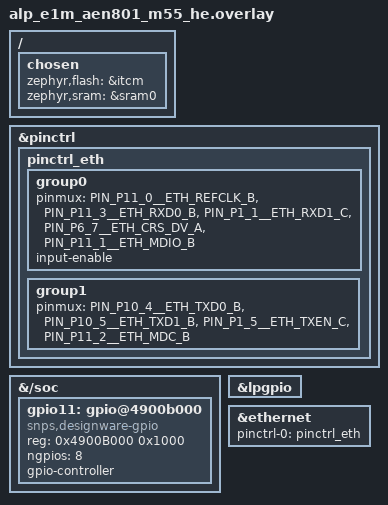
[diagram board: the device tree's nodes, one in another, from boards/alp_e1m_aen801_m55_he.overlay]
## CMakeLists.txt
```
# SPDX-License-Identifier: Apache-2.0
cmake_minimum_required(VERSION 3.20)
find_package(Zephyr REQUIRED HINTS $ENV{ZEPHYR_BASE})
project(aen_ethernet_link LANGUAGES C)
target_sources(app PRIVATE src/main.c)
```

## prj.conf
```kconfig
# SPDX-License-Identifier: Apache-2.0
#
# Bench config for the E1M-AEN801 (M55-HE). Console is the E1M edge UART0.

CONFIG_ALP_SDK=y

# Networking + Ethernet L2 + the alp-sdk Alif GMAC glue (CONFIG_ETH_DWMAC_ALIF
# selects the upstream eth_dwmac core). IPv4 on; no auto DHCP (no link on this
# bench until the PHY is powered, so a DHCP client would just spin).
CONFIG_NETWORKING=y
CONFIG_NET_L2_ETHERNET=y
CONFIG_ETH_DWMAC_ALIF=y
CONFIG_NET_IPV4=y
CONFIG_NET_IPV6=n
CONFIG_NET_UDP=y
CONFIG_NET_CONFIG_AUTO_INIT=n

# DEFINITIVE link proof: pull a DHCP lease off the bench switch (dnsmasq,
# its DHCP pool). A lease requires a genuine bidirectional link.
CONFIG_NET_DHCPV4=y
CONFIG_NET_MGMT=y
CONFIG_NET_MGMT_EVENT=y
# DHCP needs sys_rand_get (transaction IDs); no HW RNG wired -> timer PRNG
# (TEST_RANDOM_GENERATOR enables the non-crypto choice; bench link test only).
CONFIG_TEST_RANDOM_GENERATOR=y
CONFIG_NET_PKT_RX_COUNT=8
CONFIG_NET_PKT_TX_COUNT=8
CONFIG_NET_BUF_RX_COUNT=16
CONFIG_NET_BUF_TX_COUNT=16

# Per-interface RX byte stats (a secondary proof; fixed-link masks carrier).
CONFIG_NET_STATISTICS=y
CONFIG_NET_STATISTICS_PER_INTERFACE=y

# GPIO for the PHY power-down (P15_4 lpgpio) + reset (P11_6 gpio11) lines.
CONFIG_GPIO=y

CONFIG_MAIN_STACK_SIZE=4096
CONFIG_HEAP_MEM_POOL_SIZE=16384

# eth_dwmac uses DMA descriptor rings -- keep the data path coherent on the M55.
CONFIG_DCACHE=n

# Console: Alp UART console -- E1M edge UART0 (Alif UART5, P3_4/P3_5, 115200
# 8N1, NS16550), the E1M-AEN801 carrier console. The board _defconfig already
# selects it; we set it explicitly here so the example is self-describing.
CONFIG_SERIAL=y
CONFIG_CONSOLE=y
CONFIG_UART_CONSOLE=y
CONFIG_UART_INTERRUPT_DRIVEN=y
# Serial-less bench? Comment the four lines above and uncomment these to read
# 'ram_console_buf' over SWD instead:
# CONFIG_RAM_CONSOLE=y
# CONFIG_RAM_CONSOLE_BUFFER_SIZE=2048
# CONFIG_UART_CONSOLE=n
CONFIG_PRINTK=y
```

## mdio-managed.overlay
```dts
/*
 * Copyright 2026 Alp Lab AB
 * SPDX-License-Identifier: Apache-2.0
 *
 * MDIO-managed-PHY compile-only variant of the aen-ethernet-link bring-up.
 * Applied ON TOP of the board's default fixed-link overlay
 * (boards/alp_e1m_aen801_m55_he_ae822fa0e5597ls0_rtss_he.overlay, which
 * already routes the MDC/MDIO pins in pinctrl_eth): enables the `mdio`
 * controller + `eth_phy_managed` TI DP83825 child added to
 * zephyr/dts/alif/ensemble_e8_peripherals.dtsi, and repoints &ethernet's
 * phy-handle at it instead of the default fixed-link eth_phy.
 *
 * COMPILE-PROOF in CI (see the mdio-managed test entry in testcase.yaml):
 * closes that the mdio_dwmac_alif driver binds, phy_ti_dp83825 binds on the
 * bus, and the upstream eth_dwmac core's phy_link path compiles with a
 * managed PHY.
 *
 * The MDIO layer itself HAS since been exercised on real E8 silicon by a
 * Flow C ITCM RAM-run of this variant (#1244):
 *
 *   [eth] MDIO PHY@0 id=2000a140 (DP83825=2000a140)
 *   [eth] PHY regs: ANAR=01e1 ANLPAR=0000 PHYSTS=0002 RCSR=00e1
 *
 * That run reported `PHY link DOWN (BMSR=7849)` -- no cable on that desk --
 * so link/traffic over the managed path is still unproven; reading the PHY
 * ID needs no link, which is what made the address answerable without one.
 *
 * This overlay deliberately does NOT override `reg`: it inherits the PHY
 * address from `eth_phy_managed` in
 * zephyr/dts/alif/ensemble_e8_peripherals.dtsi, so there is ONE source of
 * truth for it. Keep it that way -- the fix for the wrong address (1 -> 0)
 * belongs at that node, not here.
 */

&mdio {
	status = "okay";
};

&eth_phy_managed {
	status = "okay";
};

&ethernet {
	phy-handle = <&eth_phy_managed>;
};
```

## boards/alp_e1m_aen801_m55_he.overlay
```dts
/*
 * Copyright (c) 2026 Alp Lab AB
 * SPDX-License-Identifier: Apache-2.0
 *
 * Ethernet (GMAC) bring-up overlay for the E1M-AEN801 (E8, M55-HE).
 *
 * The ethernet@48100000 node (eth_dwmac core + the alp-sdk alif,ethernet glue,
 * fixed-link RMII PHY) already lives in zephyr/dts/alif/ensemble_e8_peripherals.dtsi
 * as status="disabled"; this overlay enables it and supplies the RMII pin group +
 * a real MAC address.
 *
 * RMII PADS: the AUTHORITATIVE E1M-AEN801 routing from
 * metadata/e1m_modules/aen/alif-ethernet-phy.tsv (NOT the fork's reference route,
 * which the first cut wrongly used):
 *   REFCLK P11_0 | RXD0 P11_3 | RXD1 P1_1 | CRS_DV P6_7  (inputs)
 *   TXD0  P10_4  | TXD1 P10_5 | TXEN  P1_5               (outputs)
 * The input pads carry `input-enable` (the upstream pad REN bit, set by
 * soc/alif/ensemble/pinctrl_soc.h) so the RMII RX buffers actually sense. The PHY
 * is unmanaged (fixed-link) so MDC/MDIO (P11_2/P11_1) are not muxed.
 *
 * PHY POWER/RESET are ALIF pins (per the SoM TSV), NOT CC3501E as the first cut
 * claimed: E_PHY_PWRDWN = P15_4 (lpgpio) and E_PHY_RESET = P11_6 (gpio11). Both
 * are driven by main(); the alp-sdk E8 dtsi already carries gpio0..gpio9 AND
 * lpgpio, so lpgpio just needs status="okay" -- only gpio11 is newly created
 * here (reg/IRQ/ngpios from the fork dtsi).
 */
#include <zephyr/dt-bindings/pinctrl/alif-ensemble-pinctrl.h>

/ {
	chosen {
		zephyr,flash = &itcm; /* bench RAM/SES-load; path-ref form */
		/delete-property/ zephyr,code-partition;
		/*
		 * Put SYSTEM RAM in the global on-chip SRAM0 (sram@2000000, 4 MiB,
		 * @0x02000000 -- declared by the SoC dtsi, the same bank the NPU uses),
		 * NOT the generated default `zephyr,sram = &dtcm`. The GMAC is a DMA bus
		 * master: it fetches the descriptor rings and reads/writes the net_buf
		 * packet pool over its own AXI master. The M55 DTCM (CPU-local alias
		 * 0x20000000) is tightly-coupled and NOT on the GMAC DMA path, so rings +
		 * buffers left in DTCM are invisible to the DMA -- no frames move in
		 * EITHER direction (bench: SOM rx_bytes=0 AND the switch/server NIC RX=0).
		 * SRAM0 is globally addressed (CPU addr == DMA addr), which is exactly
		 * what the upstream DWMAC core needs (it hands the raw CPU pointer to the
		 * DMA -- no local_to_global translation). With CONFIG_DCACHE=n (prj.conf)
		 * the CPU and the DMA share a coherent view. This is the eth_dwmac glue's
		 * documented Tier-1.5 placement gap (see eth_dwmac_alif_ensemble.c header).
		 */
		zephyr,sram = &sram0;
	};
};

&pinctrl {
	pinctrl_eth: pinctrl_eth {
		/* RMII inputs (REFCLK + RX) + MDIO (bidirectional, read during MDIO
		 * transactions) -- input-enable sets the pad REN bit so they sense.
		 * MDC/MDIO = P11_2/P11_1 (SoM TSV) let us read the PHY status registers. */
		group0 {
			pinmux = <PIN_P11_0__ETH_REFCLK_B>, <PIN_P11_3__ETH_RXD0_B>,
				 <PIN_P1_1__ETH_RXD1_C>, <PIN_P6_7__ETH_CRS_DV_A>,
				 <PIN_P11_1__ETH_MDIO_B>;
			input-enable;
		};
		/* RMII outputs (TX) + MDC (MDIO clock). */
		group1 {
			pinmux = <PIN_P10_4__ETH_TXD0_B>, <PIN_P10_5__ETH_TXD1_B>,
				 <PIN_P1_5__ETH_TXEN_C>, <PIN_P11_2__ETH_MDC_B>;
		};
	};
};

/* PHY reset line E_PHY_RESET = P11_6 (gpio11 pin 6). gpio11@4900b000 from the
 * fork dts (snps,designware-gpio, ngpios 8, IRQ 267..). */
&{/soc} {
	gpio11: gpio@4900b000 {
		compatible = "snps,designware-gpio";
		reg = <0x4900B000 0x1000>;
		ngpios = <8>;
		gpio-controller;
		#gpio-cells = <2>;
		status = "okay";
	};
};

/* PHY power-down line E_PHY_PWRDWN = P15_4 (lpgpio pin 4). lpgpio@42002000
 * (AON/LP domain) already exists in the alp-sdk E8 dtsi; just enable it. */
&lpgpio {
	status = "okay";
};

&ethernet {
	pinctrl-0 = <&pinctrl_eth>;
	pinctrl-names = "default";
	/* Station MAC: inherits zephyr,random-mac-address from the SoC dtsi
	 * (per-boot random locally-administered 02:01:56:xx:xx:xx) -- DHCP
	 * doesn't care which MAC asks, and a random one means two boards on
	 * the same bench switch never collide.  To pin a fixed per-unit MAC
	 * instead:
	 *   /delete-property/ zephyr,random-mac-address;
	 *   local-mac-address = [ .. ]; */
	status = "okay";
};
```

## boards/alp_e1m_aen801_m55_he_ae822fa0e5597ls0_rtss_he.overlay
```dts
/*
 * Copyright (c) 2026 Alp Lab AB
 * SPDX-License-Identifier: Apache-2.0
 *
 * Ethernet (GMAC) bring-up overlay for the E1M-AEN801 (E8, M55-HE).
 *
 * The ethernet@48100000 node (eth_dwmac core + the alp-sdk alif,ethernet glue,
 * fixed-link RMII PHY) already lives in zephyr/dts/alif/ensemble_e8_peripherals.dtsi
 * as status="disabled"; this overlay enables it and supplies the RMII pin group +
 * a real MAC address.
 *
 * RMII PADS: the AUTHORITATIVE E1M-AEN801 routing from
 * metadata/e1m_modules/aen/alif-ethernet-phy.tsv (NOT the fork's reference route,
 * which the first cut wrongly used):
 *   REFCLK P11_0 | RXD0 P11_3 | RXD1 P1_1 | CRS_DV P6_7  (inputs)
 *   TXD0  P10_4  | TXD1 P10_5 | TXEN  P1_5               (outputs)
 * The input pads carry `input-enable` (the upstream pad REN bit, set by
 * soc/alif/ensemble/pinctrl_soc.h) so the RMII RX buffers actually sense. The PHY
 * is unmanaged (fixed-link) so MDC/MDIO (P11_2/P11_1) are not muxed.
 *
 * PHY POWER/RESET are ALIF pins (per the SoM TSV), NOT CC3501E as the first cut
 * claimed: E_PHY_PWRDWN = P15_4 (lpgpio) and E_PHY_RESET = P11_6 (gpio11). Both
 * are driven by main(); the alp-sdk E8 dtsi already carries gpio0..gpio9 AND
 * lpgpio, so lpgpio just needs status="okay" -- only gpio11 is newly created
 * here (reg/IRQ/ngpios from the fork dtsi).
 */
#include <zephyr/dt-bindings/pinctrl/alif-ensemble-pinctrl.h>

/ {
	chosen {
		zephyr,flash = &itcm; /* bench RAM/SES-load; path-ref form */
		/delete-property/ zephyr,code-partition;
		/*
		 * Main RAM stays on the generated default `zephyr,sram = &dtcm` --
		 * unlike the first cut, this overlay does NOT move all of RAM to
		 * SRAM0 (slower, and intermittently broke the ISP). The GMAC DMA
		 * still cannot reach DTCM, so only the Ethernet-owned buffers move:
		 * the ethernet node's `memory-region = <&sram0>;` (SoC dtsi) places
		 * the descriptor rings there, and CONFIG_ETH_DWMAC_ALIF_NET_BUF_IN_DMA_REGION
		 * (prj.conf) relocates the net_buf packet pool (subsys/net/ip/net_pkt.c)
		 * into the same region. See eth_dwmac_alif_ensemble.c's file header
		 * for the full placement rationale; CONFIG_DCACHE=n (prj.conf) keeps
		 * the CPU and the DMA coherent.
		 */
	};
};

&pinctrl {
	pinctrl_eth: pinctrl_eth {
		/* RMII inputs (REFCLK + RX) + MDIO (bidirectional, read during MDIO
		 * transactions) -- input-enable sets the pad REN bit so they sense.
		 * MDC/MDIO = P11_2/P11_1 (SoM TSV) let us read the PHY status registers. */
		group0 {
			pinmux = <PIN_P11_0__ETH_REFCLK_B>, <PIN_P11_3__ETH_RXD0_B>,
				 <PIN_P1_1__ETH_RXD1_C>, <PIN_P6_7__ETH_CRS_DV_A>,
				 <PIN_P11_1__ETH_MDIO_B>;
			input-enable;
		};
		/* RMII outputs (TX) + MDC (MDIO clock). */
		group1 {
			pinmux = <PIN_P10_4__ETH_TXD0_B>, <PIN_P10_5__ETH_TXD1_B>,
				 <PIN_P1_5__ETH_TXEN_C>, <PIN_P11_2__ETH_MDC_B>;
		};
	};
};

/* PHY reset line E_PHY_RESET = P11_6 (gpio11 pin 6). gpio11@4900b000 from the
 * fork dts (snps,designware-gpio, ngpios 8, IRQ 267..). */
&{/soc} {
	gpio11: gpio@4900b000 {
		compatible = "snps,designware-gpio";
		reg = <0x4900B000 0x1000>;
		ngpios = <8>;
		gpio-controller;
		#gpio-cells = <2>;
		status = "okay";
	};
};

/* PHY power-down line E_PHY_PWRDWN = P15_4 (lpgpio pin 4). lpgpio@42002000
 * (AON/LP domain) already exists in the alp-sdk E8 dtsi; just enable it. */
&lpgpio {
	status = "okay";
};

&ethernet {
	pinctrl-0 = <&pinctrl_eth>;
	pinctrl-names = "default";
	/* Station MAC: inherits zephyr,random-mac-address from the SoC dtsi
	 * (per-boot random locally-administered 02:01:56:xx:xx:xx) -- DHCP
	 * doesn't care which MAC asks, and a random one means two boards on
	 * the same bench switch never collide.  To pin a fixed per-unit MAC
	 * instead:
	 *   /delete-property/ zephyr,random-mac-address;
	 *   local-mac-address = [ .. ]; */
	status = "okay";
};
```

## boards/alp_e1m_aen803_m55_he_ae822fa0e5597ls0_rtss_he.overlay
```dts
/*
 * Copyright (c) 2026 Alp Lab AB
 * SPDX-License-Identifier: Apache-2.0
 *
 * Ethernet (GMAC) bring-up overlay for the E1M-AEN803 (E8, M55-HE).
 *
 * The ethernet@48100000 node (eth_dwmac core + the alp-sdk alif,ethernet glue,
 * fixed-link RMII PHY) already lives in zephyr/dts/alif/ensemble_e8_peripherals.dtsi
 * as status="disabled"; this overlay enables it and supplies the RMII pin group +
 * a real MAC address.
 *
 * RMII PADS: the AUTHORITATIVE E1M-AEN803 routing from
 * metadata/e1m_modules/aen/alif-ethernet-phy.tsv (NOT the fork's reference route,
 * which the first cut wrongly used):
 *   REFCLK P11_0 | RXD0 P11_3 | RXD1 P1_1 | CRS_DV P6_7  (inputs)
 *   TXD0  P10_4  | TXD1 P10_5 | TXEN  P1_5               (outputs)
 * The input pads carry `input-enable` (the upstream pad REN bit, set by
 * soc/alif/ensemble/pinctrl_soc.h) so the RMII RX buffers actually sense. The PHY
 * is unmanaged (fixed-link) so MDC/MDIO (P11_2/P11_1) are not muxed.
 *
 * PHY POWER/RESET are ALIF pins (per the SoM TSV), NOT CC3501E as the first cut
 * claimed: E_PHY_PWRDWN = P15_4 (lpgpio) and E_PHY_RESET = P11_6 (gpio11). Both
 * are driven by main(); the alp-sdk E8 dtsi already carries gpio0..gpio9 AND
 * lpgpio, so lpgpio just needs status="okay" -- only gpio11 is newly created
 * here (reg/IRQ/ngpios from the fork dtsi).
 */
#include <zephyr/dt-bindings/pinctrl/alif-ensemble-pinctrl.h>

/ {
	chosen {
		zephyr,flash = &itcm; /* bench RAM/SES-load; path-ref form */
		/delete-property/ zephyr,code-partition;
		/*
		 * Main RAM stays on the generated default `zephyr,sram = &dtcm` --
		 * unlike the first cut, this overlay does NOT move all of RAM to
		 * SRAM0 (slower, and intermittently broke the ISP). The GMAC DMA
		 * still cannot reach DTCM, so only the Ethernet-owned buffers move:
		 * the ethernet node's `memory-region = <&sram0>;` (SoC dtsi) places
		 * the descriptor rings there, and CONFIG_ETH_DWMAC_ALIF_NET_BUF_IN_DMA_REGION
		 * (prj.conf) relocates the net_buf packet pool (subsys/net/ip/net_pkt.c)
		 * into the same region. See eth_dwmac_alif_ensemble.c's file header
		 * for the full placement rationale; CONFIG_DCACHE=n (prj.conf) keeps
		 * the CPU and the DMA coherent.
		 */
	};
};

&pinctrl {
	pinctrl_eth: pinctrl_eth {
		/* RMII inputs (REFCLK + RX) + MDIO (bidirectional, read during MDIO
		 * transactions) -- input-enable sets the pad REN bit so they sense.
		 * MDC/MDIO = P11_2/P11_1 (SoM TSV) let us read the PHY status registers. */
		group0 {
			pinmux = <PIN_P11_0__ETH_REFCLK_B>, <PIN_P11_3__ETH_RXD0_B>,
				 <PIN_P1_1__ETH_RXD1_C>, <PIN_P6_7__ETH_CRS_DV_A>,
				 <PIN_P11_1__ETH_MDIO_B>;
			input-enable;
		};
		/* RMII outputs (TX) + MDC (MDIO clock). */
		group1 {
			pinmux = <PIN_P10_4__ETH_TXD0_B>, <PIN_P10_5__ETH_TXD1_B>,
				 <PIN_P1_5__ETH_TXEN_C>, <PIN_P11_2__ETH_MDC_B>;
		};
	};
};

/* PHY reset line E_PHY_RESET = P11_6 (gpio11 pin 6). gpio11@4900b000 from the
 * fork dts (snps,designware-gpio, ngpios 8, IRQ 267..). */
&{/soc} {
	gpio11: gpio@4900b000 {
		compatible = "snps,designware-gpio";
		reg = <0x4900B000 0x1000>;
		ngpios = <8>;
		gpio-controller;
		#gpio-cells = <2>;
		status = "okay";
	};
};

/* PHY power-down line E_PHY_PWRDWN = P15_4 (lpgpio pin 4). lpgpio@42002000
 * (AON/LP domain) already exists in the alp-sdk E8 dtsi; just enable it. */
&lpgpio {
	status = "okay";
};

&ethernet {
	pinctrl-0 = <&pinctrl_eth>;
	pinctrl-names = "default";
	/* Station MAC: inherits zephyr,random-mac-address from the SoC dtsi
	 * (per-boot random locally-administered 02:01:56:xx:xx:xx) -- DHCP
	 * doesn't care which MAC asks, and a random one means two boards on
	 * the same bench switch never collide.  To pin a fixed per-unit MAC
	 * instead:
	 *   /delete-property/ zephyr,random-mac-address;
	 *   local-mac-address = [ .. ]; */
	status = "okay";
};
```

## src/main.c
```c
/*
 * Copyright (c) 2026 Alp Lab AB
 * SPDX-License-Identifier: Apache-2.0
 *
 * aen-ethernet-link -- bring up the Ensemble E8 GMAC (eth_dwmac core + the
 * alp-sdk "alif,ethernet" glue) on the E1M-AEN801 (M55-HE), power the on-module
 * TI DP83825 PHY (exact order code TBD -- metadata/chips/dp83825.yaml), and
 * test the link by pulling a DHCP lease off the bench switch.
 *
 * The MAC/driver/DT live in the SoC dtsi (ethernet@48100000, fixed-link RMII PHY);
 * the board overlay enables the node with the AUTHORITATIVE SoM RMII pin route
 * (alif-ethernet-phy.tsv) + input-enable on the RX pads, and adds the PHY control
 * GPIOs. This app:
 *   1. powers the PHY EARLY (SYS_INIT, before the eth driver's RMII ref-clock
 *      probe) -- E_PHY_PWRDWN=P15_4 (lpgpio.4) + E_PHY_RESET=P11_6 (gpio11.6).
 *      These are ALIF pins (per the SoM TSV), NOT CC3501E as first assumed.
 *   2. reads back which ref-clock source the driver's AUTO probe locked.
 *   3. requests a DHCP lease as the definitive end-to-end link test.
 *
 * RESULT PASS (bench-validated, both sides): the SOM pulls a real DHCP lease off
 * the bench switch (an address from the DHCP pool) and is REACHABLE in the server's ARP
 * table. Three things had to be right, in order:
 *   1. PHY power before the probe -> the AUTO probe selects the EXTERNAL 50 MHz
 *      oscillator (ETH_CTRL bit4: 1->0); the PHY is clocked. The "needs power
 *      enable" the bench called out IS this P15_4 enable.
 *   2. PHY RMII clock mode: RCSR bit7 REF_CLK_SEL=1 (50 MHz ref) -> media link up
 *      (BMSR bit2, 0x786d). bit7=0 keeps it down (0x7849).
 *   3. THE DECISIVE FIX -- DMA buffers off the DTCM. The board defaults
 *      `zephyr,sram = &dtcm`, so the GMAC descriptor rings + net_buf pool sat in
 *      the M55 DTCM, which is NOT on the GMAC DMA's bus -> zero frames moved
 *      either way (SOM rx_bytes=0 AND server NIC RX=0) even with the link up.
 *      Main RAM stays on DTCM (`zephyr,sram = &dtcm`, unchanged by this
 *      overlay) -- only the Ethernet-owned buffers move, via the SoC dtsi's
 *      ethernet node `memory-region = <&sram0>;` (descriptor rings) and
 *      CONFIG_ETH_DWMAC_ALIF_NET_BUF_IN_DMA_REGION (net_buf pool,
 *      subsys/net/ip/net_pkt.c), @0x02000000, CPU addr == DMA addr,
 *      + CONFIG_DCACHE=n. Silicon-verified on E1M-AEN803 (bench run 202:
 *      DHCP lease + ping, rings/pools in SRAM0, main RAM on DTCM);
 *      E1M-AEN801 is build-verified only. See the overlay and the
 *      eth_dwmac_alif_ensemble.c header (its documented Tier-1.5 gap).
 *
 * PASS gate: a DHCP lease is acquired (full bidirectional link). carrier_ok is
 * fixed-link synthetic (no managed PHY) and is NOT a link proof; the lease is.
 * PHY GPIO polarity is the conventional DP83825 reading (PWRDWN enable HIGH;
 * RST_N active-low).
 */

#include <stdio.h>
#include <errno.h>
#include <inttypes.h>

#include <zephyr/kernel.h>
#include <zephyr/init.h>
#include <zephyr/device.h>
#include <zephyr/drivers/gpio.h>
#include <zephyr/drivers/pinctrl.h>
#include <zephyr/dt-bindings/pinctrl/alif-ensemble-pinctrl.h>
#include <zephyr/sys/sys_io.h>
#include <zephyr/sys/util.h>
#include <zephyr/net/net_if.h>
#include <zephyr/net/ethernet.h>
#include <zephyr/net/dhcpv4.h>
#include <zephyr/net/net_ip.h>

#define PHY_RESET_PIN  6 /* E_PHY_RESET  = P11_6 (gpio11) */
#define PHY_PWRDWN_PIN 4 /* E_PHY_PWRDWN = P15_4 (lpgpio) */
#define LINK_SETTLE_MS 3000

/* Pad-mux states: gpio_dw applies no mux, so select the GPIO/LPGPIO function on
 * the two PHY-control pads through the Alif pinctrl driver (function 0). */
static const pinctrl_soc_pin_t phy_reset_mux[]  = { PIN_P11_6__GPIO };
static const pinctrl_soc_pin_t phy_pwrdwn_mux[] = { PIN_P15_4__LPGPIO };

/*
 * Power + reset the PHY EARLY -- at POST_KERNEL priority 50, AFTER the GPIO
 * controllers (40) but BEFORE the eth_dwmac driver (ETH_INIT_PRIORITY=60). The
 * glue's RMII ref-clock AUTO probe runs inside eth init and falls back to the
 * internal PLL if it sees no external 50 MHz clock at that moment; powering the
 * PHY/oscillator here (before that probe) lets the probe find the external clock
 * if the board just needed the enable. (When this ran later, in main(), the probe
 * had already fallen back -- SWD showed ETH_CTRL bit4=1 = internal PLL.)
 */
static int phy_power_init(void)
{
	const struct device *gpio11 = DEVICE_DT_GET(DT_NODELABEL(gpio11));
	const struct device *lpgpio = DEVICE_DT_GET(DT_NODELABEL(lpgpio));

	if (!device_is_ready(gpio11) || !device_is_ready(lpgpio)) {
		return -ENODEV;
	}

	pinctrl_configure_pins(phy_reset_mux, ARRAY_SIZE(phy_reset_mux), 0U);
	pinctrl_configure_pins(phy_pwrdwn_mux, ARRAY_SIZE(phy_pwrdwn_mux), 0U);

	/* Power-enable the PHY/oscillator. The user calls this a "power enable", so
	 * E_PHY_PWRDWN gates a board power switch (active-HIGH enable) -> drive HIGH.
	 * (SWD-verified the lpgpio follows; the SoM TSV gives the pad, not the
	 * polarity -- flip to low if this powers it down.) */
	gpio_pin_configure(lpgpio, PHY_PWRDWN_PIN, GPIO_OUTPUT_ACTIVE);
	gpio_pin_set(lpgpio, PHY_PWRDWN_PIN, 1);
	k_busy_wait(50000); /* let the PHY supply + its reference clock stabilize */

	/* Reset pulse, conventional DP83825 RST_N (active-low): LOW asserts, HIGH
	 * releases. Long assert + post-reset settle so the reference clock is stable
	 * across the reset (a clock that isn't stable at deassert leaves the analog
	 * front-end uninitialised). Both reset polarities were bench-tried. */
	gpio_pin_configure(gpio11, PHY_RESET_PIN, GPIO_OUTPUT_ACTIVE);
	gpio_pin_set(gpio11, PHY_RESET_PIN, 0); /* assert */
	k_busy_wait(50000);
	gpio_pin_set(gpio11, PHY_RESET_PIN, 1); /* release */
	k_busy_wait(100000);                    /* DP83825 post-reset settle (>=50 ms) */
	return 0;
}
/* Priority 50: gpio_dw(40) < 50 < eth_dwmac(ETH_INIT_PRIORITY 60). */
SYS_INIT(phy_power_init, POST_KERNEL, 50);

/*
 * Raw MDIO read via the DWMAC MAC_MDIO registers (GMAC base 0x48100000): the
 * fixed-link config does no MDIO, so we read the PHY directly to diagnose the
 * link. MAC_MDIO_ADDRESS=0x200 (PA[25:21], RDA[20:16], CR[11:8], GOC read=bit3+
 * bit2, GB=bit0), MAC_MDIO_DATA=0x204 (data[15:0]). CR=4 -> slow, safe MDC.
 */
#define GMAC_MDIO_ADDR 0x48100200U
#define GMAC_MDIO_DATA 0x48100204U

/*
 * Bounded wait for GB (busy) to clear BEFORE issuing a transaction. Unbounded,
 * a GMAC whose clock was never enabled (net_if_up skipped or failed) holds GB
 * and hangs the caller before any result line prints. On timeout we fall
 * through and issue anyway; the post-issue wait is bounded too, and the read
 * then yields a non-PHY value that the scan/link checks report as a FAIL.
 */
static void mdio_wait_idle(void)
{
	for (int i = 0; i < 100000 && (sys_read32(GMAC_MDIO_ADDR) & BIT(0)) != 0U; i++) {
		k_busy_wait(1);
	}
}

static uint16_t mdio_read(uint8_t phy, uint8_t reg)
{
	mdio_wait_idle();
	uint32_t a =
	    ((uint32_t)phy << 21) | ((uint32_t)reg << 16) | (0x4U << 8) | BIT(3) | BIT(2) | BIT(0);
	sys_write32(a, GMAC_MDIO_ADDR);
	for (int i = 0; i < 100000 && (sys_read32(GMAC_MDIO_ADDR) & BIT(0)); i++) {
		k_busy_wait(1);
	}
	return (uint16_t)(sys_read32(GMAC_MDIO_DATA) & 0xFFFFU);
}

static void mdio_write(uint8_t phy, uint8_t reg, uint16_t val)
{
	mdio_wait_idle();
	sys_write32(val, GMAC_MDIO_DATA);
	uint32_t a = ((uint32_t)phy << 21) | ((uint32_t)reg << 16) | (0x4U << 8) | BIT(2) | BIT(0);
	sys_write32(a, GMAC_MDIO_ADDR);
	for (int i = 0; i < 100000 && (sys_read32(GMAC_MDIO_ADDR) & BIT(0)); i++) {
		k_busy_wait(1);
	}
}

/* Find the PHY (returns addr 0-31, or -1). DP83825 OUI = 0x2000a140 (die/OUI
 * identity only; does not distinguish DP83825 grade/package suffixes). */
static int phy_find(void)
{
	for (uint8_t phy = 0; phy < 32; phy++) {
		uint16_t id1 = mdio_read(phy, 2);
		if (id1 != 0xFFFF && id1 != 0x0000) {
			printf(
			    "[eth] MDIO PHY@%u id=%04x%04x (DP83825=2000a140)\n", phy, id1, mdio_read(phy, 3));
			return phy;
		}
	}
	return -1;
}

/* Restart auto-negotiation and poll BMSR (reg 1) for link-up (bit 2) +
 * autoneg-done (bit 5). Returns true if the link comes up within ~8 s. */
static bool phy_wait_link(int phy)
{
	/*
	 * Put the PHY in 50 MHz-reference RMII mode: RCSR(0x17) bit7 REF_CLK_SEL=1
	 * (== phy_ti_dp83825's DP83825_RMII). Bench-confirmed: with bit7=1 the PHY
	 * forms a media link (BMSR bit2 set, 0x786d); with bit7=0 it does not
	 * (0x7849) -- so this board feeds the PHY's REF_CLK an external 50 MHz, and
	 * the PHY must be the RMII slave. (The data plane stalling separately turned
	 * out to be a DMA-buffers-in-DTCM placement bug, not this clock mode.)
	 */
	uint16_t rcsr = mdio_read(phy, 0x17);
	mdio_write(phy, 0x17, rcsr | BIT(7));
	printf("[eth] RCSR 0x%04x -> 0x%04x (REF_CLK_SEL=50MHz ref)\n", rcsr, mdio_read(phy, 0x17));

	mdio_write(phy, 0, BIT(12) | BIT(9)); /* BMCR: auto-neg enable + restart */
	for (int i = 0; i < 32; i++) {
		k_msleep(250);
		uint16_t bmsr = mdio_read(phy, 1);
		if ((bmsr & BIT(2)) && (bmsr & BIT(5))) {
			printf("[eth] PHY link UP after %d ms (BMSR=%04x ANLPAR=%04x)\n",
			       (i + 1) * 250,
			       bmsr,
			       mdio_read(phy, 0x05));
			return true;
		}
	}
	printf("[eth] PHY link DOWN after 8s (BMSR=%04x ANLPAR=%04x)\n",
	       mdio_read(phy, 1),
	       mdio_read(phy, 0x05));
	return false;
}

int main(void)
{
	struct net_if *iface = net_if_get_default();

	if (iface == NULL) {
		printf("[eth] RESULT FAIL: no default net interface\n[eth] done\n");
		return 0;
	}

	struct net_linkaddr *la = net_if_get_link_addr(iface);
	printf("[eth] iface %p, MAC %02x:%02x:%02x:%02x:%02x:%02x\n",
	       (void *)iface,
	       la->addr[0],
	       la->addr[1],
	       la->addr[2],
	       la->addr[3],
	       la->addr[4],
	       la->addr[5]);

	printf("[eth] PHY powered early (SYS_INIT pri 50, before the eth refclk probe)\n");

	/* Read back the RMII ref-clock source the driver's AUTO probe settled on
	 * (ETH_CTRL bit4: 0 = external P11_0 oscillator, 1 = internal-PLL fallback).
	 * External => the MAC DMA-reset completed on the on-module 50 MHz oscillator,
	 * i.e. the PHY power-enable made the external clock present BEFORE the probe --
	 * the key "needs power enable" fix, and the PHY is now clocked. */
	/* ETH_CTRL @ 0x4903F080, bit4 = RMII refclk source. Address + bit
	 * bench-observed on the E8 over SWD during this eth bring-up (the AUTO probe
	 * latched bit4 here); not transcribed from a public TRM -- treat as bench-
	 * derived, confirm against the Alif HW config before reusing elsewhere. */
	bool refclk_external = (sys_read32(0x4903F080U) & BIT(4)) == 0U;
	printf("[eth] RMII refclk source = %s (ETH_CTRL bit4=%d)\n",
	       refclk_external ? "EXTERNAL osc (PHY clocked -- power-enable worked)"
	                       : "internal PLL (external osc not detected)",
	       refclk_external ? 0 : 1);

	int rc = net_if_up(iface);
	printf("[eth] net_if_up -> %d%s\n", rc, (rc == -EALREADY) ? " (already up)" : "");

	/* Read the PHY over MDIO (fixed-link is blind to the real wire state), restart
	 * auto-neg, and wait for the link to actually come up before trying DHCP. */
	int phy = phy_find();
	if (phy >= 0) {
		/* DP83825 state: ANAR(4)=our advert, ANLPAR(5)=partner advert (0 => not
		 * hearing the switch = no RX/clock/cable), PHYSTS(0x10)=link/speed,
		 * RCSR(0x17)=RMII mode/clock-select. */
		printf("[eth] PHY regs: ANAR=%04x ANLPAR=%04x PHYSTS=%04x RCSR=%04x\n",
		       mdio_read(phy, 0x04),
		       mdio_read(phy, 0x05),
		       mdio_read(phy, 0x10),
		       mdio_read(phy, 0x17));
	}
	/* Restart auto-neg and wait for the wire link to come up. */
	bool link = (phy >= 0) && phy_wait_link(phy);

	/* End-to-end proof: with the link up, pull a DHCP lease off the bench switch
	 * (dnsmasq). A lease completes only over a genuinely live bidirectional link. */
	bool bound = false;
	if (link) {
		net_dhcpv4_start(iface);
		for (int i = 0; i < 30; i++) { /* up to ~15 s for DISCOVER/OFFER/REQUEST/ACK */
			if (iface->config.dhcpv4.state == NET_DHCPV4_BOUND) {
				bound = true;
				break;
			}
			k_msleep(500);
		}
	}

	printf("[eth] admin_up=%d carrier_ok=%d wire_link=%d rx_bytes=%" PRIu64 " dhcp_bound=%d\n",
	       net_if_is_admin_up(iface),
	       net_if_is_carrier_ok(iface),
	       link,
	       iface->stats.bytes.received,
	       bound);

	if (bound) {
		char                ip[NET_IPV4_ADDR_LEN] = { 0 };
		struct net_if_addr *ua                    = &iface->config.ip.ipv4->unicast[0].ipv4;
		net_addr_ntop(AF_INET, &ua->address.in_addr, ip, sizeof(ip));
		printf("[eth] DHCP lease = %s\n", ip);
	}

	printf("[eth] RESULT %s: %s\n",
	       (link && bound) ? "PASS" : "PARTIAL",
	       (link && bound) ? "wire link UP + DHCP lease acquired = Ethernet fully WORKING"
	       : link          ? "PHY wire link UP (auto-neg complete) but no DHCP lease -- check the "
	                         "DHCP server / IP path"
	                       : "PHY link DOWN -- check cable / switch port / PHY reference clock");
	printf("[eth] done\n");
	return 0;
}
```
